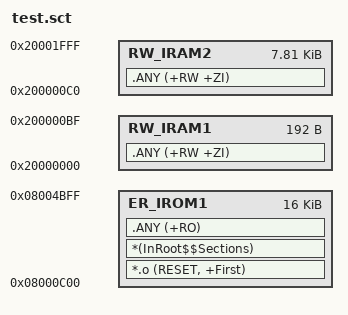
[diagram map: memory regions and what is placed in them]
; *************************************************************
; *** Scatter-Loading Description File generated by uVision ***
; *************************************************************

LR_IROM1 0x08000C00 0x00004000  {    ; load region size_region
  ER_IROM1 0x08000C00 0x00004000  {  ; load address = execution address
   *.o (RESET, +First)
   *(InRoot$$Sections)
   .ANY (+RO)
  }
  RW_IRAM1 0x20000000 0x000000C0  {  ; RW data
   .ANY (+RW +ZI)
  }
  RW_IRAM2 0x200000C0 0x00001F40  {
   .ANY (+RW +ZI)
  }
}

